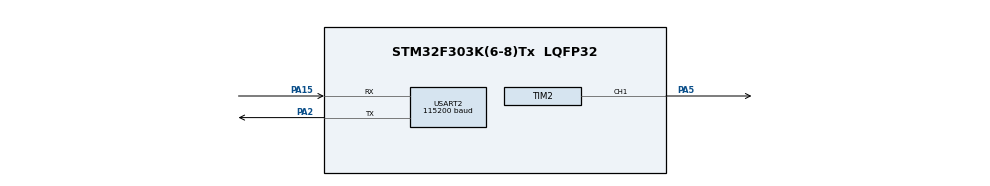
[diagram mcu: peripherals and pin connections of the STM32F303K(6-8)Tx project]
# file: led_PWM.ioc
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Dma.Request0=USART2_RX
Dma.Request1=USART2_TX
Dma.USART2_RX.0.Direction=DMA_PERIPH_TO_MEMORY
Dma.USART2_RX.0.Instance=DMA1_Channel6
Dma.USART2_RX.0.MemDataAlignment=DMA_MDATAALIGN_BYTE
Dma.USART2_RX.0.MemInc=DMA_MINC_ENABLE
Dma.USART2_RX.0.Mode=DMA_NORMAL
Dma.USART2_RX.0.PeriphDataAlignment=DMA_PDATAALIGN_BYTE
Dma.USART2_RX.0.PeriphInc=DMA_PINC_DISABLE
Dma.USART2_RX.0.Priority=DMA_PRIORITY_MEDIUM
Dma.USART2_TX.1.Direction=DMA_MEMORY_TO_PERIPH
Dma.USART2_TX.1.Instance=DMA1_Channel7
Dma.USART2_TX.1.MemDataAlignment=DMA_MDATAALIGN_BYTE
Dma.USART2_TX.1.MemInc=DMA_MINC_ENABLE
Dma.USART2_TX.1.Mode=DMA_NORMAL
Dma.USART2_TX.1.PeriphDataAlignment=DMA_PDATAALIGN_BYTE
Dma.USART2_TX.1.PeriphInc=DMA_PINC_DISABLE
Dma.USART2_TX.1.Priority=DMA_PRIORITY_MEDIUM
Mcu.Family=STM32F3
Mcu.Name=STM32F303K(6-8)Tx
Mcu.Package=LQFP32
NVIC.DMA1_Channel6_IRQn=true\:0\:0\:false\:false\:true\:false\:true
NVIC.DMA1_Channel7_IRQn=true\:0\:0\:false\:false\:true\:false\:true
NVIC.PriorityGroup=NVIC_PRIORITYGROUP_4
NVIC.TIM2_IRQn=true\:0\:0\:false\:false\:true\:true\:true
NVIC.USART2_IRQn=true\:0\:0\:false\:false\:true\:true\:true
PA15.Mode=Asynchronous
PA15.Signal=USART2_RX
PA2.Mode=Asynchronous
PA2.Signal=USART2_TX
PA5.Signal=S_TIM2_CH1_ETR
ProjectManager.HeapSize=0x200
ProjectManager.StackSize=0x400
ProjectManager.TargetToolchain=STM32CubeIDE
RCC.AHBFreq_Value=8000000
RCC.APB1Freq_Value=8000000
RCC.APB1TimFreq_Value=8000000
RCC.APB2Freq_Value=8000000
RCC.APB2TimFreq_Value=8000000
RCC.CortexFreq_Value=8000000
RCC.HCLKFreq_Value=8000000
RCC.HSE_VALUE=8000000
RCC.HSI_VALUE=8000000
RCC.PLLMUL=RCC_PLL_MUL4
RCC.SYSCLKFreq_VALUE=8000000
SH.S_TIM2_CH1_ETR.0=TIM2_CH1,PWM Generation1 CH1
TIM2.Channel-PWM\ Generation1\ CH1=TIM_CHANNEL_1
TIM2.ClockDivision=TIM_CLOCKDIVISION_DIV4
TIM2.Period=99
TIM2.Prescaler=19999
USART2.BaudRate=115200
USART2.VirtualMode-Asynchronous=VM_ASYNC
VP_TIM2_VS_ClockSourceINT.Mode=Internal
board=custom

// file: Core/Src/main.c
/* USER CODE BEGIN Header */
/**
  ******************************************************************************
  * @file           : main.c
  * @brief          : Main program body
  ******************************************************************************
  * @attention
  *
  * <h2><center>&copy; Copyright (c) 2021 STMicroelectronics.
  * All rights reserved.</center></h2>
  *
  * This software component is licensed by ST under BSD 3-Clause license,
  * the "License"; You may not use this file except in compliance with the
  * License. You may obtain a copy of the License at:
  *                        opensource.org/licenses/BSD-3-Clause
  *
  ******************************************************************************
  */
/* USER CODE END Header */
#include "main.h"
#include "dma.h"
#include "tim.h"
#include "usart.h"
#include "gpio.h"
#include <string.h>
#include <stdlib.h>

void SystemClock_Config(void);
void processDMAData(const uint8_t *data, uint8_t length);

/* USER CODE BEGIN 0 */

uint8_t count = 0;

/* USER CODE END 0 */

int main(void)
{

  /* MCU Configuration--------------------------------------------------------*/

  /* Reset of all peripherals, Initializes the Flash interface and the Systick. */

  LL_APB2_GRP1_EnableClock(LL_APB2_GRP1_PERIPH_SYSCFG);
  LL_APB1_GRP1_EnableClock(LL_APB1_GRP1_PERIPH_PWR);

  NVIC_SetPriorityGrouping(NVIC_PRIORITYGROUP_4);

  /* System interrupt init*/

  /* Configure the system clock */
  SystemClock_Config();

  /* Initialize all configured peripherals */
  MX_GPIO_Init();
  MX_DMA_Init();
  MX_USART2_UART_Init();
  MX_TIM2_Init();
  USART2_RegisterCallback(processDMAData);
  /* USER CODE BEGIN 2 */

  uint8_t c[] = "mode: %d\n\r";
  uint8_t number = 0;

  /* USER CODE END 2 */

  /* Infinite loop */
  while (1)
  {
	  uint8_t length = strlen("mode: \n\r") + snprintf( NULL, 0, "%d", number);
	  uint8_t *text = (uint8_t *) malloc(length + 1);
	  snprintf(text, length + 1, c, number);

	// USART2_CheckDmaReception();
	// USART2_PutBuffer(text, length+1);
	/* USER CODE BEGIN 3 */
	LL_mDelay(10000);
  }
  /* USER CODE END 3 */
}

void SystemClock_Config(void)
{
  LL_FLASH_SetLatency(LL_FLASH_LATENCY_0);
  while(LL_FLASH_GetLatency()!= LL_FLASH_LATENCY_0)
  {
  }
  LL_RCC_HSI_Enable();

   /* Wait till HSI is ready */
  while(LL_RCC_HSI_IsReady() != 1)
  {

  }
  LL_RCC_HSI_SetCalibTrimming(16);
  LL_RCC_SetAHBPrescaler(LL_RCC_SYSCLK_DIV_1);
  LL_RCC_SetAPB1Prescaler(LL_RCC_APB1_DIV_1);
  LL_RCC_SetAPB2Prescaler(LL_RCC_APB1_DIV_1);
  LL_RCC_SetSysClkSource(LL_RCC_SYS_CLKSOURCE_HSI);

   /* Wait till System clock is ready */
  while(LL_RCC_GetSysClkSource() != LL_RCC_SYS_CLKSOURCE_STATUS_HSI)
  {

  }
  LL_Init1msTick(8000000);
  LL_SetSystemCoreClock(8000000);
}

/* USER CODE BEGIN 4 */
void processDMAData(const uint8_t *data, uint8_t length){

	uint8_t *cmd_auto = "auto";
	uint8_t *cmd_manual = "manual";
	uint8_t *cmd_pwm = "PWM";

	uint8_t start_parsing = 0;
	uint8_t start_idx = 0;
	uint8_t end_idx = 0;
	uint8_t is_cmd = 0;

	for (uint8_t i = 0; i < length; i++){

	        if (data[i] == '$' && !start_parsing){
	            start_parsing = 1;
	            start_idx = i + 1;
	        }
	        else if (data[i] == '$' && start_parsing){
	            start_parsing = 0;
	            end_idx = i - 1;
	            is_cmd = 1;
	        }
	    }

	    if (is_cmd){
	    uint8_t data_length = end_idx - start_idx + 1;
	    uint8_t *temp_data = (uint8_t *) malloc(data_length + 1);
	    strncpy(temp_data, (data + start_idx), data_length);
	    temp_data[data_length] = '\0';

	    if (strcmp(cmd_auto, temp_data) == 0){
       	    mode_auto = 1;
	    }
	    else if (strcmp(cmd_manual, temp_data) == 0){
	   	    mode_auto = 0;
	    }

	    if (!mode_auto && strlen(temp_data) == 5 && strncmp(cmd_pwm, temp_data, 3)==0){
	    	uint8_t decimals = temp_data[3]-48;
	    	uint8_t ones = temp_data[4]-48;
	    	if((0 <= decimals <= 9) && (0 <= ones <= 9)){
	    		new_pwm = decimals*10 + ones;
	    	}
	    }
   }
}

/* USER CODE END 4 */

void Error_Handler(void)
{
  __disable_irq();
  while (1)
  {
  }
}

/************************ (C) COPYRIGHT STMicroelectronics *****END OF FILE****/
